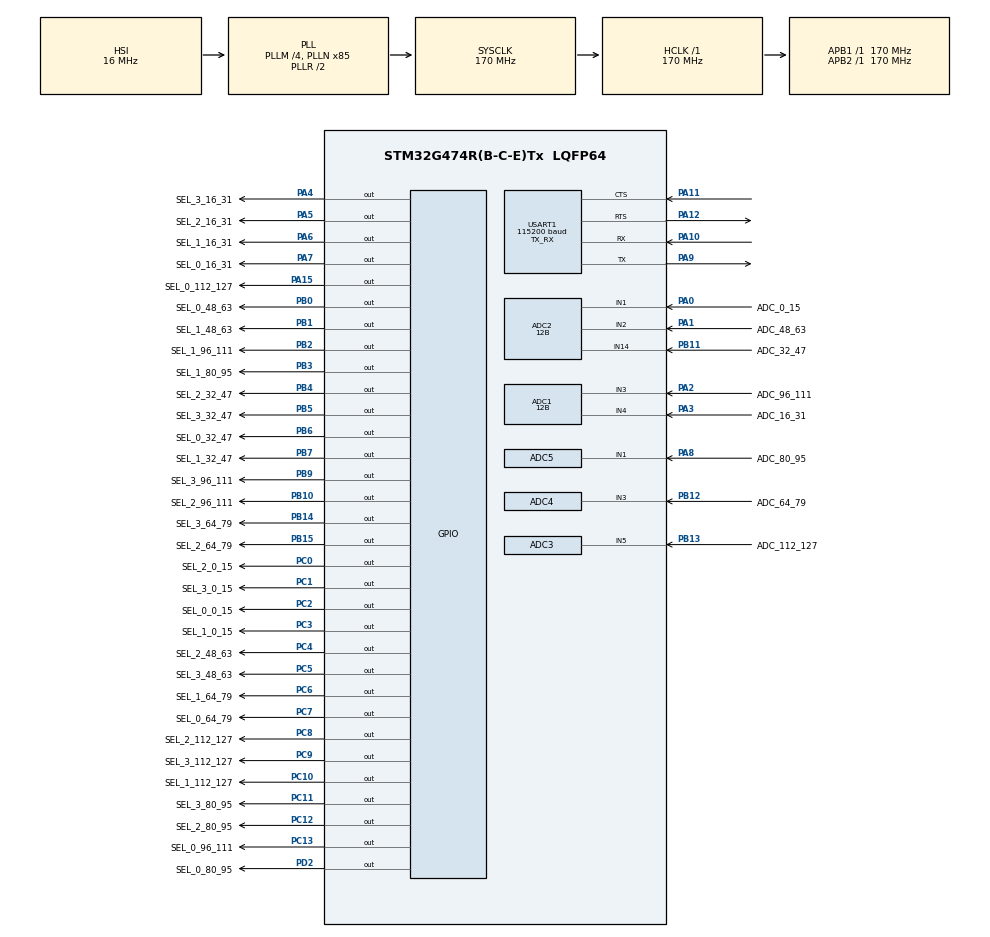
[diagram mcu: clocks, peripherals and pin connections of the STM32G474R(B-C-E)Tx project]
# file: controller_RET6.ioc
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ADC1.Channel-1\#ChannelRegularConversion=ADC_CHANNEL_3
ADC1.Channel-2\#ChannelRegularConversion=ADC_CHANNEL_4
ADC1.Channel-IN3=ADC_CHANNEL_3
ADC1.Channel-IN4=ADC_CHANNEL_4
ADC1.ClockPrescaler=ADC_CLOCK_SYNC_PCLK_DIV4
ADC1.ContinuousConvMode=DISABLE
ADC1.DMAContinuousRequests=ENABLE
ADC1.DataAlign=ADC_DATAALIGN_RIGHT
ADC1.DiscontinuousConvMode=DISABLE
ADC1.EOCSelection=ADC_EOC_SINGLE_CONV
ADC1.EnableAnalogWatchDog1=false
ADC1.EnableAnalogWatchDog2=false
ADC1.EnableAnalogWatchDog3=false
ADC1.EnableInjectedConversion=DISABLE
ADC1.EnableRegularConversion=ENABLE
ADC1.ExternalTrigConv=ADC_SOFTWARE_START
ADC1.ExternalTrigConvEdge=ADC_EXTERNALTRIGCONVEDGE_NONE
ADC1.GainCompensation=0
ADC1.LowPowerAutoWait=DISABLE
ADC1.Mode=ADC_MODE_INDEPENDENT
ADC1.NbrOfConversion=2
ADC1.OffsetNumber-1\#ChannelRegularConversion=ADC_OFFSET_NONE
ADC1.OffsetNumber-2\#ChannelRegularConversion=ADC_OFFSET_NONE
ADC1.Overrun=ADC_OVR_DATA_PRESERVED
ADC1.OversamplingMode=DISABLE
ADC1.Rank-1\#ChannelRegularConversion=1
ADC1.Rank-2\#ChannelRegularConversion=2
ADC1.Resolution=ADC_RESOLUTION_12B
ADC1.SamplingTime-1\#ChannelRegularConversion=ADC_SAMPLETIME_2CYCLES_5
ADC1.SamplingTime-2\#ChannelRegularConversion=ADC_SAMPLETIME_2CYCLES_5
ADC1.ScanConvMode=ADC_SCAN_ENABLE
ADC1.master=1
ADC2.Channel-1\#ChannelRegularConversion=ADC_CHANNEL_1
ADC2.Channel-2\#ChannelRegularConversion=ADC_CHANNEL_2
ADC2.Channel-3\#ChannelRegularConversion=ADC_CHANNEL_14
ADC2.Channel-IN1=ADC_CHANNEL_1
ADC2.Channel-IN14=ADC_CHANNEL_14
ADC2.Channel-IN2=ADC_CHANNEL_2
ADC2.ClockPrescaler=ADC_CLOCK_SYNC_PCLK_DIV4
ADC2.ContinuousConvMode=DISABLE
ADC2.DMAContinuousRequests=ENABLE
ADC2.DataAlign=ADC_DATAALIGN_RIGHT
ADC2.DiscontinuousConvMode=DISABLE
ADC2.EOCSelection=ADC_EOC_SINGLE_CONV
ADC2.EnableAnalogWatchDog1=false
ADC2.EnableAnalogWatchDog2=false
ADC2.EnableAnalogWatchDog3=false
ADC2.EnableInjectedConversion=DISABLE
ADC2.EnableRegularConversion=ENABLE
ADC2.ExternalTrigConv=ADC_SOFTWARE_START
ADC2.ExternalTrigConvEdge=ADC_EXTERNALTRIGCONVEDGE_NONE
ADC2.GainCompensation=0
ADC2.LowPowerAutoWait=DISABLE
ADC2.Mode=ADC_MODE_INDEPENDENT
ADC2.NbrOfConversion=3
ADC2.OffsetNumber-1\#ChannelRegularConversion=ADC_OFFSET_NONE
ADC2.OffsetNumber-2\#ChannelRegularConversion=ADC_OFFSET_NONE
ADC2.OffsetNumber-3\#ChannelRegularConversion=ADC_OFFSET_NONE
ADC2.Overrun=ADC_OVR_DATA_PRESERVED
ADC2.OversamplingMode=DISABLE
ADC2.Rank-1\#ChannelRegularConversion=1
ADC2.Rank-2\#ChannelRegularConversion=2
ADC2.Rank-3\#ChannelRegularConversion=3
ADC2.Resolution=ADC_RESOLUTION_12B
ADC2.SamplingTime-1\#ChannelRegularConversion=ADC_SAMPLETIME_2CYCLES_5
ADC2.SamplingTime-2\#ChannelRegularConversion=ADC_SAMPLETIME_2CYCLES_5
ADC2.SamplingTime-3\#ChannelRegularConversion=ADC_SAMPLETIME_2CYCLES_5
ADC2.ScanConvMode=ADC_SCAN_ENABLE
ADC3.Channel-0\#ChannelRegularConversion=ADC_CHANNEL_5
ADC3.Channel-IN5=ADC_CHANNEL_5
ADC3.ClockPrescaler=ADC_CLOCK_SYNC_PCLK_DIV4
ADC3.ContinuousConvMode=DISABLE
ADC3.DMAContinuousRequests=ENABLE
ADC3.DataAlign=ADC_DATAALIGN_RIGHT
ADC3.DiscontinuousConvMode=DISABLE
ADC3.EOCSelection=ADC_EOC_SINGLE_CONV
ADC3.EnableAnalogWatchDog1=false
ADC3.EnableAnalogWatchDog2=false
ADC3.EnableAnalogWatchDog3=false
ADC3.EnableInjectedConversion=DISABLE
ADC3.EnableRegularConversion=ENABLE
ADC3.ExternalTrigConv=ADC_SOFTWARE_START
ADC3.ExternalTrigConvEdge=ADC_EXTERNALTRIGCONVEDGE_NONE
ADC3.GainCompensation=0
ADC3.LowPowerAutoWait=DISABLE
ADC3.Mode=ADC_MODE_INDEPENDENT
ADC3.NbrOfConversion=1
ADC3.OffsetNumber-0\#ChannelRegularConversion=ADC_OFFSET_NONE
ADC3.Overrun=ADC_OVR_DATA_PRESERVED
ADC3.OversamplingMode=DISABLE
ADC3.Rank-0\#ChannelRegularConversion=1
ADC3.Resolution=ADC_RESOLUTION_12B
ADC3.SamplingTime-0\#ChannelRegularConversion=ADC_SAMPLETIME_2CYCLES_5
ADC3.ScanConvMode=ADC_SCAN_DISABLE
ADC3.master=1
ADC4.Channel-0\#ChannelRegularConversion=ADC_CHANNEL_3
ADC4.Channel-IN3=ADC_CHANNEL_3
ADC4.ClockPrescaler=ADC_CLOCK_SYNC_PCLK_DIV4
ADC4.ContinuousConvMode=DISABLE
ADC4.DMAContinuousRequests=ENABLE
ADC4.DataAlign=ADC_DATAALIGN_RIGHT
ADC4.DiscontinuousConvMode=DISABLE
ADC4.EOCSelection=ADC_EOC_SINGLE_CONV
ADC4.EnableAnalogWatchDog1=false
ADC4.EnableAnalogWatchDog2=false
ADC4.EnableAnalogWatchDog3=false
ADC4.EnableInjectedConversion=DISABLE
ADC4.EnableRegularConversion=ENABLE
ADC4.ExternalTrigConv=ADC_SOFTWARE_START
ADC4.ExternalTrigConvEdge=ADC_EXTERNALTRIGCONVEDGE_NONE
ADC4.GainCompensation=0
ADC4.LowPowerAutoWait=DISABLE
ADC4.Mode=ADC_MODE_INDEPENDENT
ADC4.NbrOfConversion=1
ADC4.OffsetNumber-0\#ChannelRegularConversion=ADC_OFFSET_NONE
ADC4.Overrun=ADC_OVR_DATA_PRESERVED
ADC4.OversamplingMode=DISABLE
ADC4.Rank-0\#ChannelRegularConversion=1
ADC4.Resolution=ADC_RESOLUTION_12B
ADC4.SamplingTime-0\#ChannelRegularConversion=ADC_SAMPLETIME_2CYCLES_5
ADC4.ScanConvMode=ADC_SCAN_DISABLE
ADC5.Channel-0\#ChannelRegularConversion=ADC_CHANNEL_1
ADC5.Channel-IN1=ADC_CHANNEL_1
ADC5.ClockPrescaler=ADC_CLOCK_SYNC_PCLK_DIV4
ADC5.ContinuousConvMode=DISABLE
ADC5.DMAContinuousRequests=ENABLE
ADC5.DataAlign=ADC_DATAALIGN_RIGHT
ADC5.DiscontinuousConvMode=DISABLE
ADC5.EOCSelection=ADC_EOC_SINGLE_CONV
ADC5.EnableAnalogWatchDog1=false
ADC5.EnableAnalogWatchDog2=false
ADC5.EnableAnalogWatchDog3=false
ADC5.EnableInjectedConversion=DISABLE
ADC5.EnableRegularConversion=ENABLE
ADC5.ExternalTrigConv=ADC_SOFTWARE_START
ADC5.ExternalTrigConvEdge=ADC_EXTERNALTRIGCONVEDGE_NONE
ADC5.GainCompensation=0
ADC5.LowPowerAutoWait=DISABLE
ADC5.NbrOfConversion=1
ADC5.OffsetNumber-0\#ChannelRegularConversion=ADC_OFFSET_NONE
ADC5.Overrun=ADC_OVR_DATA_PRESERVED
ADC5.OversamplingMode=DISABLE
ADC5.Rank-0\#ChannelRegularConversion=1
ADC5.Resolution=ADC_RESOLUTION_12B
ADC5.SamplingTime-0\#ChannelRegularConversion=ADC_SAMPLETIME_2CYCLES_5
ADC5.ScanConvMode=ADC_SCAN_DISABLE
CRC.DefaultInitValueUse=DEFAULT_INIT_VALUE_ENABLE
CRC.DefaultPolynomialUse=DEFAULT_POLYNOMIAL_ENABLE
CRC.InputDataFormat=CRC_INPUTDATA_FORMAT_BYTES
CRC.InputDataInversionMode=CRC_INPUTDATA_INVERSION_NONE
CRC.OutputDataInversionMode=CRC_OUTPUTDATA_INVERSION_DISABLE
Dma.ADC1.3.Direction=DMA_PERIPH_TO_MEMORY
Dma.ADC1.3.EventEnable=DISABLE
Dma.ADC1.3.Instance=DMA1_Channel2
Dma.ADC1.3.MemDataAlignment=DMA_MDATAALIGN_HALFWORD
Dma.ADC1.3.MemInc=DMA_MINC_ENABLE
Dma.ADC1.3.Mode=DMA_CIRCULAR
Dma.ADC1.3.PeriphDataAlignment=DMA_PDATAALIGN_HALFWORD
Dma.ADC1.3.PeriphInc=DMA_PINC_DISABLE
Dma.ADC1.3.Polarity=HAL_DMAMUX_REQ_GEN_RISING
Dma.ADC1.3.Priority=DMA_PRIORITY_VERY_HIGH
Dma.ADC1.3.RequestNumber=1
Dma.ADC1.3.SignalID=NONE
Dma.ADC1.3.SyncEnable=DISABLE
Dma.ADC1.3.SyncPolarity=HAL_DMAMUX_SYNC_NO_EVENT
Dma.ADC1.3.SyncRequestNumber=1
Dma.ADC1.3.SyncSignalID=NONE
Dma.ADC2.1.Direction=DMA_PERIPH_TO_MEMORY
Dma.ADC2.1.EventEnable=DISABLE
Dma.ADC2.1.Instance=DMA1_Channel3
Dma.ADC2.1.MemDataAlignment=DMA_MDATAALIGN_HALFWORD
Dma.ADC2.1.MemInc=DMA_MINC_ENABLE
Dma.ADC2.1.Mode=DMA_CIRCULAR
Dma.ADC2.1.PeriphDataAlignment=DMA_PDATAALIGN_HALFWORD
Dma.ADC2.1.PeriphInc=DMA_PINC_DISABLE
Dma.ADC2.1.Polarity=HAL_DMAMUX_REQ_GEN_RISING
Dma.ADC2.1.Priority=DMA_PRIORITY_VERY_HIGH
Dma.ADC2.1.RequestNumber=1
Dma.ADC2.1.SignalID=NONE
Dma.ADC2.1.SyncEnable=DISABLE
Dma.ADC2.1.SyncPolarity=HAL_DMAMUX_SYNC_NO_EVENT
Dma.ADC2.1.SyncRequestNumber=1
Dma.ADC2.1.SyncSignalID=NONE
Dma.ADC3.5.Direction=DMA_PERIPH_TO_MEMORY
Dma.ADC3.5.EventEnable=DISABLE
Dma.ADC3.5.Instance=DMA1_Channel4
Dma.ADC3.5.MemDataAlignment=DMA_MDATAALIGN_HALFWORD
Dma.ADC3.5.MemInc=DMA_MINC_ENABLE
Dma.ADC3.5.Mode=DMA_CIRCULAR
Dma.ADC3.5.PeriphDataAlignment=DMA_PDATAALIGN_HALFWORD
Dma.ADC3.5.PeriphInc=DMA_PINC_DISABLE
Dma.ADC3.5.Polarity=HAL_DMAMUX_REQ_GEN_RISING
Dma.ADC3.5.Priority=DMA_PRIORITY_VERY_HIGH
Dma.ADC3.5.RequestNumber=1
Dma.ADC3.5.SignalID=NONE
Dma.ADC3.5.SyncEnable=DISABLE
Dma.ADC3.5.SyncPolarity=HAL_DMAMUX_SYNC_NO_EVENT
Dma.ADC3.5.SyncRequestNumber=1
Dma.ADC3.5.SyncSignalID=NONE
Dma.ADC4.0.Direction=DMA_PERIPH_TO_MEMORY
Dma.ADC4.0.EventEnable=DISABLE
Dma.ADC4.0.Instance=DMA1_Channel5
Dma.ADC4.0.MemDataAlignment=DMA_MDATAALIGN_HALFWORD
Dma.ADC4.0.MemInc=DMA_MINC_ENABLE
Dma.ADC4.0.Mode=DMA_CIRCULAR
Dma.ADC4.0.PeriphDataAlignment=DMA_PDATAALIGN_HALFWORD
Dma.ADC4.0.PeriphInc=DMA_PINC_DISABLE
Dma.ADC4.0.Polarity=HAL_DMAMUX_REQ_GEN_RISING
Dma.ADC4.0.Priority=DMA_PRIORITY_VERY_HIGH
Dma.ADC4.0.RequestNumber=1
Dma.ADC4.0.SignalID=NONE
Dma.ADC4.0.SyncEnable=DISABLE
Dma.ADC4.0.SyncPolarity=HAL_DMAMUX_SYNC_NO_EVENT
Dma.ADC4.0.SyncRequestNumber=1
Dma.ADC4.0.SyncSignalID=NONE
Dma.ADC5.4.Direction=DMA_PERIPH_TO_MEMORY
Dma.ADC5.4.EventEnable=DISABLE
Dma.ADC5.4.Instance=DMA1_Channel6
Dma.ADC5.4.MemDataAlignment=DMA_MDATAALIGN_HALFWORD
Dma.ADC5.4.MemInc=DMA_MINC_ENABLE
Dma.ADC5.4.Mode=DMA_CIRCULAR
Dma.ADC5.4.PeriphDataAlignment=DMA_PDATAALIGN_HALFWORD
Dma.ADC5.4.PeriphInc=DMA_PINC_DISABLE
Dma.ADC5.4.Polarity=HAL_DMAMUX_REQ_GEN_RISING
Dma.ADC5.4.Priority=DMA_PRIORITY_VERY_HIGH
Dma.ADC5.4.RequestNumber=1
Dma.ADC5.4.SignalID=NONE
Dma.ADC5.4.SyncEnable=DISABLE
Dma.ADC5.4.SyncPolarity=HAL_DMAMUX_SYNC_NO_EVENT
Dma.ADC5.4.SyncRequestNumber=1
Dma.ADC5.4.SyncSignalID=NONE
Dma.Request0=ADC4
Dma.Request1=ADC2
Dma.Request2=USART1_TX
Dma.Request3=ADC1
Dma.Request4=ADC5
Dma.Request5=ADC3
Dma.USART1_TX.2.Direction=DMA_MEMORY_TO_PERIPH
Dma.USART1_TX.2.EventEnable=DISABLE
Dma.USART1_TX.2.Instance=DMA1_Channel1
Dma.USART1_TX.2.MemDataAlignment=DMA_MDATAALIGN_BYTE
Dma.USART1_TX.2.MemInc=DMA_MINC_ENABLE
Dma.USART1_TX.2.Mode=DMA_CIRCULAR
Dma.USART1_TX.2.PeriphDataAlignment=DMA_PDATAALIGN_BYTE
Dma.USART1_TX.2.PeriphInc=DMA_PINC_DISABLE
Dma.USART1_TX.2.Polarity=HAL_DMAMUX_REQ_GEN_RISING
Dma.USART1_TX.2.Priority=DMA_PRIORITY_MEDIUM
Dma.USART1_TX.2.RequestNumber=1
Dma.USART1_TX.2.SignalID=NONE
Dma.USART1_TX.2.SyncEnable=DISABLE
Dma.USART1_TX.2.SyncPolarity=HAL_DMAMUX_SYNC_NO_EVENT
Dma.USART1_TX.2.SyncRequestNumber=1
Dma.USART1_TX.2.SyncSignalID=NONE
HRTIM1.ADCTrigger_Id1=__NULL
HRTIM1.ADCTrigger_Id10=__NULL
HRTIM1.ADCTrigger_Id2=__NULL
HRTIM1.ADCTrigger_Id3=__NULL
HRTIM1.ADCTrigger_Id4=__NULL
HRTIM1.ADCTrigger_Id5=__NULL
HRTIM1.ADCTrigger_Id6=__NULL
HRTIM1.ADCTrigger_Id7=__NULL
HRTIM1.ADCTrigger_Id8=__NULL
HRTIM1.ADCTrigger_Id9=__NULL
HRTIM1.BurstDMAconfig-MasterTimer=__NULL
HRTIM1.BurstDMAconfig-No_output_TA=__NULL
HRTIM1.BurstDMAconfig-No_output_TB=__NULL
HRTIM1.BurstDMAconfig-No_output_TC=__NULL
HRTIM1.BurstMode-MasterTimer=HRTIM_TIMERBURSTMODE_MAINTAINCLOCK
HRTIM1.BurstMode-No_output_TA=HRTIM_TIMERBURSTMODE_MAINTAINCLOCK
HRTIM1.BurstMode-No_output_TB=HRTIM_TIMERBURSTMODE_MAINTAINCLOCK
HRTIM1.BurstMode-No_output_TC=HRTIM_TIMERBURSTMODE_MAINTAINCLOCK
HRTIM1.CalibrationRate_nonIT=HRTIM_CALIBRATIONRATE_3
HRTIM1.CaptureUnit1-No_output_TA=__NULL
HRTIM1.CaptureUnit1-No_output_TB=__NULL
HRTIM1.CaptureUnit1-No_output_TC=__NULL
HRTIM1.CaptureUnit2-No_output_TA=__NULL
HRTIM1.CaptureUnit2-No_output_TB=__NULL
HRTIM1.CaptureUnit2-No_output_TC=__NULL
HRTIM1.CompareUnit1-MasterTimer=__NULL
HRTIM1.CompareUnit1-No_output_TA=__NULL
HRTIM1.CompareUnit1-No_output_TB=__NULL
HRTIM1.CompareUnit1-No_output_TC=__NULL
HRTIM1.CompareUnit2-MasterTimer=__NULL
HRTIM1.CompareUnit2-No_output_TA=__NULL
HRTIM1.CompareUnit2-No_output_TB=__NULL
HRTIM1.CompareUnit2-No_output_TC=__NULL
HRTIM1.CompareUnit3-MasterTimer=__NULL
HRTIM1.CompareUnit3-No_output_TA=__NULL
HRTIM1.CompareUnit3-No_output_TB=__NULL
HRTIM1.CompareUnit3-No_output_TC=__NULL
HRTIM1.CompareUnit4-MasterTimer=__NULL
HRTIM1.CompareUnit4-No_output_TA=__NULL
HRTIM1.CompareUnit4-No_output_TB=__NULL
HRTIM1.CompareUnit4-No_output_TC=__NULL
HRTIM1.Configuration_TA=Waveform
HRTIM1.Configuration_TB=Waveform
HRTIM1.Configuration_TC=Waveform
HRTIM1.DACSynchro-MasterTimer=HRTIM_DACSYNC_NONE
HRTIM1.DACSynchro-No_output_TA=HRTIM_DACSYNC_NONE
HRTIM1.DACSynchro-No_output_TB=HRTIM_DACSYNC_NONE
HRTIM1.DACSynchro-No_output_TC=HRTIM_DACSYNC_NONE
HRTIM1.DeadTimeInsertion-No_output_TA=HRTIM_TIMDEADTIMEINSERTION_DISABLED
HRTIM1.DeadTimeInsertion-No_output_TB=HRTIM_TIMDEADTIMEINSERTION_DISABLED
HRTIM1.DeadTimeInsertion-No_output_TC=HRTIM_TIMDEADTIMEINSERTION_DISABLED
HRTIM1.DelayedProtectionMode-No_output_TA=HRTIM_TIMER_A_B_C_DELAYEDPROTECTION_DISABLED
HRTIM1.DelayedProtectionMode-No_output_TB=HRTIM_TIMER_A_B_C_DELAYEDPROTECTION_DISABLED
HRTIM1.DelayedProtectionMode-No_output_TC=HRTIM_TIMER_A_B_C_DELAYEDPROTECTION_DISABLED
HRTIM1.DualChannelDacEnableFake_TA-No_output_TA=HRTIM_TIMER_DCDE_DISABLED
HRTIM1.DualChannelDacEnableFake_TB-No_output_TB=HRTIM_TIMER_DCDE_DISABLED
HRTIM1.DualChannelDacEnableFake_TC-No_output_TC=HRTIM_TIMER_DCDE_DISABLED
HRTIM1.Enable=HRTIM_BURSTMODECTL_DISABLED
HRTIM1.EnableCalibration=DLLSimpleCalibration
HRTIM1.Event1-No_output_TA=__NULL
HRTIM1.Event1-No_output_TB=__NULL
HRTIM1.Event1-No_output_TC=__NULL
HRTIM1.Event10-No_output_TA=__NULL
HRTIM1.Event10-No_output_TB=__NULL
HRTIM1.Event10-No_output_TC=__NULL
HRTIM1.Event2-No_output_TA=__NULL
HRTIM1.Event2-No_output_TB=__NULL
HRTIM1.Event2-No_output_TC=__NULL
HRTIM1.Event3-No_output_TA=__NULL
HRTIM1.Event3-No_output_TB=__NULL
HRTIM1.Event3-No_output_TC=__NULL
HRTIM1.Event4-No_output_TA=__NULL
HRTIM1.Event4-No_output_TB=__NULL
HRTIM1.Event4-No_output_TC=__NULL
HRTIM1.Event5-No_output_TA=__NULL
HRTIM1.Event5-No_output_TB=__NULL
HRTIM1.Event5-No_output_TC=__NULL
HRTIM1.Event6-No_output_TA=__NULL
HRTIM1.Event6-No_output_TB=__NULL
HRTIM1.Event6-No_output_TC=__NULL
HRTIM1.Event7-No_output_TA=__NULL
HRTIM1.Event7-No_output_TB=__NULL
HRTIM1.Event7-No_output_TC=__NULL
HRTIM1.Event8-No_output_TA=__NULL
HRTIM1.Event8-No_output_TB=__NULL
HRTIM1.Event8-No_output_TC=__NULL
HRTIM1.Event9-No_output_TA=__NULL
HRTIM1.Event9-No_output_TB=__NULL
HRTIM1.Event9-No_output_TC=__NULL
HRTIM1.EventEnableA-No_output_TA=__NULL
HRTIM1.EventEnableA-No_output_TB=__NULL
HRTIM1.EventEnableA-No_output_TC=__NULL
HRTIM1.Event_EEV1=__NULL
HRTIM1.Event_EEV10=__NULL
HRTIM1.Event_EEV2=__NULL
HRTIM1.Event_EEV3=__NULL
HRTIM1.Event_EEV4=__NULL
HRTIM1.Event_EEV5=__NULL
HRTIM1.Event_EEV6=__NULL
HRTIM1.Event_EEV7=__NULL
HRTIM1.Event_EEV8=__NULL
HRTIM1.Event_EEV9=__NULL
HRTIM1.FaultLock-No_output_TA=HRTIM_TIMFAULTLOCK_READWRITE
HRTIM1.FaultLock-No_output_TB=HRTIM_TIMFAULTLOCK_READWRITE
HRTIM1.FaultLock-No_output_TC=HRTIM_TIMFAULTLOCK_READWRITE
HRTIM1.Fault_Line1=__NULL
HRTIM1.Fault_Line2=__NULL
HRTIM1.Fault_Line3=__NULL
HRTIM1.Fault_Line4=__NULL
HRTIM1.Fault_Line5=__NULL
HRTIM1.Fault_Line6=__NULL
HRTIM1.HRTIMInterruptResquests1=HRTIM_IT_SYSFLT
HRTIM1.HRTIMInterruptResquests2=HRTIM_IT_SYSFLT
HRTIM1.HRTIMInterruptResquests3=HRTIM_IT_SYSFLT
HRTIM1.HRTIMInterruptResquests4=HRTIM_IT_SYSFLT
HRTIM1.HRTIMInterruptResquests5=HRTIM_IT_SYSFLT
HRTIM1.HRTIMInterruptResquests6=HRTIM_IT_SYSFLT
HRTIM1.HRTIMInterruptResquests7=HRTIM_IT_SYSFLT
HRTIM1.HRTIMInterruptResquests8=HRTIM_IT_SYSFLT
HRTIM1.HRTIMInterruptResquests9=HRTIM_IT_SYSFLT
HRTIM1.InterleavedMode-MasterTimer=HRTIM_INTERLEAVED_MODE_DISABLED
HRTIM1.InterleavedMode-No_output_TA=HRTIM_INTERLEAVED_MODE_DISABLED
HRTIM1.InterleavedMode-No_output_TB=HRTIM_INTERLEAVED_MODE_DISABLED
HRTIM1.InterleavedMode-No_output_TC=HRTIM_INTERLEAVED_MODE_DISABLED
HRTIM1.InterruptRequests1-No_output_TA=HRTIM_TIM_IT_REP
HRTIM1.InterruptRequests1-No_output_TB=HRTIM_TIM_IT_REP
HRTIM1.InterruptRequests1-No_output_TC=HRTIM_TIM_IT_REP
HRTIM1.ModeTimeBase-MasterTimer=HRTIM_MODE_CONTINUOUS
HRTIM1.ModeTimeBase-No_output_TA=HRTIM_MODE_CONTINUOUS
HRTIM1.ModeTimeBase-No_output_TB=HRTIM_MODE_CONTINUOUS
HRTIM1.ModeTimeBase-No_output_TC=HRTIM_MODE_CONTINUOUS
HRTIM1.NumberDMARequests_Master=0
HRTIM1.NumberDMARequests_TA=0
HRTIM1.NumberDMARequests_TB=0
HRTIM1.NumberDMARequests_TC=0
HRTIM1.NumberFaultEnable-No_output_TA=0
HRTIM1.NumberFaultEnable-No_output_TB=0
HRTIM1.NumberFaultEnable-No_output_TC=0
HRTIM1.NumberInterruptRequests-No_output_TA=1
HRTIM1.NumberInterruptRequests-No_output_TB=1
HRTIM1.NumberInterruptRequests-No_output_TC=1
HRTIM1.NumberInterruptRequests_Master-MasterTimer=0
HRTIM1.NumberResetTrigger-No_output_TA=0
HRTIM1.NumberResetTrigger-No_output_TB=0
HRTIM1.NumberResetTrigger-No_output_TC=0
HRTIM1.NumberUpdateTrigger-No_output_TA=0
HRTIM1.NumberUpdateTrigger-No_output_TB=0
HRTIM1.NumberUpdateTrigger-No_output_TC=0
HRTIM1.Periode_MASTER=96
HRTIM1.Periode_TA=0x7695
HRTIM1.Periode_TB=0xFFFD
HRTIM1.PreloadEnable-MasterTimer=HRTIM_PRELOAD_DISABLED
HRTIM1.PreloadEnable-No_output_TA=HRTIM_PRELOAD_ENABLED
HRTIM1.PreloadEnable-No_output_TB=HRTIM_PRELOAD_ENABLED
HRTIM1.PreloadEnable-No_output_TC=HRTIM_PRELOAD_ENABLED
HRTIM1.PrescalerRatio_MASTER=HRTIM_PRESCALERRATIO_MUL32
HRTIM1.PrescalerRatio_TA=HRTIM_PRESCALERRATIO_DIV4
HRTIM1.PrescalerRatio_TB=HRTIM_PRESCALERRATIO_DIV4
HRTIM1.PrescalerRatio_TC=HRTIM_PRESCALERRATIO_DIV4
HRTIM1.PushPull-No_output_TA=HRTIM_TIMPUSHPULLMODE_DISABLED
HRTIM1.PushPull-No_output_TB=HRTIM_TIMPUSHPULLMODE_DISABLED
HRTIM1.PushPull-No_output_TC=HRTIM_TIMPUSHPULLMODE_DISABLED
HRTIM1.ReSyncUpdate-No_output_TA=HRTIM_TIMERESYNC_UPDATE_UNCONDITIONAL
HRTIM1.ReSyncUpdate-No_output_TB=HRTIM_TIMERESYNC_UPDATE_UNCONDITIONAL
HRTIM1.ReSyncUpdate-No_output_TC=HRTIM_TIMERESYNC_UPDATE_UNCONDITIONAL
HRTIM1.RepetitionUpdate-MasterTimer=HRTIM_UPDATEONREPETITION_DISABLED
HRTIM1.RepetitionUpdate-No_output_TA=HRTIM_UPDATEONREPETITION_ENABLED
HRTIM1.RepetitionUpdate-No_output_TB=HRTIM_UPDATEONREPETITION_ENABLED
HRTIM1.RepetitionUpdate-No_output_TC=HRTIM_UPDATEONREPETITION_ENABLED
HRTIM1.ResetOnSync-MasterTimer=HRTIM_SYNCRESET_DISABLED
HRTIM1.ResetOnSync-No_output_TA=HRTIM_SYNCRESET_DISABLED
HRTIM1.ResetOnSync-No_output_TB=HRTIM_SYNCRESET_DISABLED
HRTIM1.ResetOnSync-No_output_TC=HRTIM_SYNCRESET_DISABLED
HRTIM1.ResetUpdate-No_output_TA=HRTIM_TIMUPDATEONRESET_DISABLED
HRTIM1.ResetUpdate-No_output_TB=HRTIM_TIMUPDATEONRESET_DISABLED
HRTIM1.ResetUpdate-No_output_TC=HRTIM_TIMUPDATEONRESET_DISABLED
HRTIM1.StartOnSync-MasterTimer=HRTIM_SYNCSTART_DISABLED
HRTIM1.StartOnSync-No_output_TA=HRTIM_SYNCSTART_DISABLED
HRTIM1.StartOnSync-No_output_TB=HRTIM_SYNCSTART_DISABLED
HRTIM1.StartOnSync-No_output_TC=HRTIM_SYNCSTART_DISABLED
HRTIM1.SyncOptions=HRTIM_SYNCOPTION_NONE
HRTIM1.Timeout=10
HRTIM1.TimerIdx-MasterTimer=HRTIM_TIMERINDEX_MASTER
HRTIM1.TimerIdx-No_output_TA=HRTIM_TIMERINDEX_TIMER_A
HRTIM1.TimerIdx-No_output_TB=HRTIM_TIMERINDEX_TIMER_B
HRTIM1.TimerIdx-No_output_TC=HRTIM_TIMERINDEX_TIMER_C
HRTIM1.UpDownMode-No_output_TA=HRTIM_TIMERUPDOWNMODE_UP
HRTIM1.UpDownMode-No_output_TB=HRTIM_TIMERUPDOWNMODE_UP
HRTIM1.UpDownMode-No_output_TC=HRTIM_TIMERUPDOWNMODE_UP
HRTIM1.UpdateGating-MasterTimer=HRTIM_UPDATEGATING_INDEPENDENT
HRTIM1.UpdateGating-No_output_TA=HRTIM_UPDATEGATING_INDEPENDENT
HRTIM1.UpdateGating-No_output_TB=HRTIM_UPDATEGATING_INDEPENDENT
HRTIM1.UpdateGating-No_output_TC=HRTIM_UPDATEGATING_INDEPENDENT
Mcu.Family=STM32G4
Mcu.Name=STM32G474R(B-C-E)Tx
Mcu.Package=LQFP64
NVIC.DMA1_Channel1_IRQn=true\:0\:0\:false\:false\:true\:false\:true\:true
NVIC.DMA1_Channel2_IRQn=true\:0\:0\:false\:false\:true\:false\:true\:true
NVIC.DMA1_Channel3_IRQn=true\:0\:0\:false\:false\:true\:false\:true\:true
NVIC.DMA1_Channel4_IRQn=true\:0\:0\:false\:false\:true\:false\:true\:true
NVIC.DMA1_Channel5_IRQn=true\:0\:0\:false\:false\:true\:false\:true\:true
NVIC.DMA1_Channel6_IRQn=true\:0\:0\:false\:false\:true\:false\:true\:true
NVIC.HRTIM1_FLT_IRQn=true\:5\:0\:true\:false\:true\:true\:true\:true
NVIC.HRTIM1_Master_IRQn=true\:5\:0\:true\:false\:true\:true\:true\:true
NVIC.HRTIM1_TIMA_IRQn=true\:5\:0\:true\:false\:true\:true\:true\:true
NVIC.HRTIM1_TIMB_IRQn=true\:0\:0\:false\:false\:true\:true\:true\:true
NVIC.HRTIM1_TIMC_IRQn=true\:0\:0\:false\:false\:true\:true\:true\:true
NVIC.PriorityGroup=NVIC_PRIORITYGROUP_4
NVIC.TIM1_UP_TIM16_IRQn=true\:5\:0\:true\:false\:true\:true\:true\:true
NVIC.USART1_IRQn=true\:0\:0\:false\:false\:true\:true\:true\:true
PA0.GPIO_Label=ADC_0_15
PA0.Mode=IN1-Single-Ended
PA0.Signal=ADC2_IN1
PA1.GPIO_Label=ADC_48_63
PA1.Mode=IN2-Single-Ended
PA1.Signal=ADC2_IN2
PA10.Mode=Asynchronous
PA10.Signal=USART1_RX
PA11.Mode=CTS_RTS
PA11.Signal=USART1_CTS
PA12.Mode=CTS_RTS
PA12.Signal=USART1_RTS
PA13.Mode=Serial_Wire
PA13.Signal=SYS_JTMS-SWDIO
PA14.Mode=Serial_Wire
PA14.Signal=SYS_JTCK-SWCLK
PA15.GPIO_Label=SEL_0_112_127
PA15.GPIO_Speed=GPIO_SPEED_FREQ_VERY_HIGH
PA15.Signal=GPIO_Output
PA2.GPIO_Label=ADC_96_111
PA2.Mode=IN3-Single-Ended
PA2.Signal=ADC1_IN3
PA3.GPIO_Label=ADC_16_31
PA3.Mode=IN4-Single-Ended
PA3.Signal=ADC1_IN4
PA4.GPIO_Label=SEL_3_16_31
PA4.GPIO_Speed=GPIO_SPEED_FREQ_VERY_HIGH
PA4.Signal=GPIO_Output
PA5.GPIO_Label=SEL_2_16_31
PA5.GPIO_Speed=GPIO_SPEED_FREQ_VERY_HIGH
PA5.Signal=GPIO_Output
PA6.GPIO_Label=SEL_1_16_31
PA6.GPIO_Speed=GPIO_SPEED_FREQ_VERY_HIGH
PA6.Signal=GPIO_Output
PA7.GPIO_Label=SEL_0_16_31
PA7.GPIO_Speed=GPIO_SPEED_FREQ_VERY_HIGH
PA7.Signal=GPIO_Output
PA8.GPIO_Label=ADC_80_95
PA8.Mode=IN1-Single-Ended
PA8.Signal=ADC5_IN1
PA9.Mode=Asynchronous
PA9.Signal=USART1_TX
PB0.GPIO_Label=SEL_0_48_63
PB0.GPIO_Speed=GPIO_SPEED_FREQ_VERY_HIGH
PB0.Signal=GPIO_Output
PB1.GPIO_Label=SEL_1_48_63
PB1.GPIO_Speed=GPIO_SPEED_FREQ_VERY_HIGH
PB1.Signal=GPIO_Output
PB10.GPIO_Label=SEL_2_96_111
PB10.GPIO_Speed=GPIO_SPEED_FREQ_VERY_HIGH
PB10.Signal=GPIO_Output
PB11.GPIO_Label=ADC_32_47
PB11.Mode=IN14-Single-Ended
PB11.Signal=ADC2_IN14
PB12.GPIO_Label=ADC_64_79
PB12.Mode=IN3-Single-Ended
PB12.Signal=ADC4_IN3
PB13.GPIO_Label=ADC_112_127
PB13.Mode=IN5-Single-Ended
PB13.Signal=ADC3_IN5
PB14.GPIO_Label=SEL_3_64_79
PB14.GPIO_Speed=GPIO_SPEED_FREQ_VERY_HIGH
PB14.Signal=GPIO_Output
PB15.GPIO_Label=SEL_2_64_79
PB15.GPIO_Speed=GPIO_SPEED_FREQ_VERY_HIGH
PB15.Signal=GPIO_Output
PB2.GPIO_Label=SEL_1_96_111
PB2.GPIO_Speed=GPIO_SPEED_FREQ_VERY_HIGH
PB2.Signal=GPIO_Output
PB3.GPIO_Label=SEL_1_80_95
PB3.GPIO_Speed=GPIO_SPEED_FREQ_VERY_HIGH
PB3.Signal=GPIO_Output
PB4.GPIO_Label=SEL_2_32_47
PB4.GPIO_Speed=GPIO_SPEED_FREQ_VERY_HIGH
PB4.Signal=GPIO_Output
PB5.GPIO_Label=SEL_3_32_47
PB5.GPIO_Speed=GPIO_SPEED_FREQ_VERY_HIGH
PB5.Signal=GPIO_Output
PB6.GPIO_FM6=SYSCFG_FASTMODEPLUS_PB6
PB6.GPIO_Label=SEL_0_32_47
PB6.GPIO_Speed=GPIO_SPEED_FREQ_VERY_HIGH
PB6.Signal=GPIO_Output
PB7.GPIO_FM7=SYSCFG_FASTMODEPLUS_PB7
PB7.GPIO_Label=SEL_1_32_47
PB7.GPIO_Speed=GPIO_SPEED_FREQ_VERY_HIGH
PB7.Signal=GPIO_Output
PB9.GPIO_FM9=SYSCFG_FASTMODEPLUS_PB9
PB9.GPIO_Label=SEL_3_96_111
PB9.GPIO_Speed=GPIO_SPEED_FREQ_VERY_HIGH
PB9.Signal=GPIO_Output
PC0.GPIO_Label=SEL_2_0_15
PC0.GPIO_Speed=GPIO_SPEED_FREQ_VERY_HIGH
PC0.Signal=GPIO_Output
PC1.GPIO_Label=SEL_3_0_15
PC1.GPIO_Speed=GPIO_SPEED_FREQ_VERY_HIGH
PC1.Signal=GPIO_Output
PC10.GPIO_Label=SEL_1_112_127
PC10.GPIO_Speed=GPIO_SPEED_FREQ_VERY_HIGH
PC10.Signal=GPIO_Output
PC11.GPIO_Label=SEL_3_80_95
PC11.GPIO_Speed=GPIO_SPEED_FREQ_VERY_HIGH
PC11.Signal=GPIO_Output
PC12.GPIO_Label=SEL_2_80_95
PC12.GPIO_Speed=GPIO_SPEED_FREQ_VERY_HIGH
PC12.Signal=GPIO_Output
PC13.GPIO_Label=SEL_0_96_111
PC13.GPIO_Speed=GPIO_SPEED_FREQ_LOW
PC13.Signal=GPIO_Output
PC14-OSC32_IN.Mode=LSE-External-Oscillator
PC14-OSC32_IN.Signal=RCC_OSC32_IN
PC15-OSC32_OUT.Mode=LSE-External-Oscillator
PC15-OSC32_OUT.Signal=RCC_OSC32_OUT
PC2.GPIO_Label=SEL_0_0_15
PC2.GPIO_Speed=GPIO_SPEED_FREQ_VERY_HIGH
PC2.Signal=GPIO_Output
PC3.GPIO_Label=SEL_1_0_15
PC3.GPIO_Speed=GPIO_SPEED_FREQ_VERY_HIGH
PC3.Signal=GPIO_Output
PC4.GPIO_Label=SEL_2_48_63
PC4.GPIO_Speed=GPIO_SPEED_FREQ_VERY_HIGH
PC4.Signal=GPIO_Output
PC5.GPIO_Label=SEL_3_48_63
PC5.GPIO_Speed=GPIO_SPEED_FREQ_VERY_HIGH
PC5.Signal=GPIO_Output
PC6.GPIO_Label=SEL_1_64_79
PC6.GPIO_Speed=GPIO_SPEED_FREQ_VERY_HIGH
PC6.Signal=GPIO_Output
PC7.GPIO_Label=SEL_0_64_79
PC7.GPIO_Speed=GPIO_SPEED_FREQ_VERY_HIGH
PC7.Signal=GPIO_Output
PC8.GPIO_Label=SEL_2_112_127
PC8.GPIO_Speed=GPIO_SPEED_FREQ_VERY_HIGH
PC8.Signal=GPIO_Output
PC9.GPIO_Label=SEL_3_112_127
PC9.GPIO_Speed=GPIO_SPEED_FREQ_VERY_HIGH
PC9.Signal=GPIO_Output
PD2.GPIO_Label=SEL_0_80_95
PD2.GPIO_Speed=GPIO_SPEED_FREQ_VERY_HIGH
PD2.Signal=GPIO_Output
PF0-OSC_IN.Mode=HSE-External-Oscillator
PF0-OSC_IN.Signal=RCC_OSC_IN
PF1-OSC_OUT.Mode=HSE-External-Oscillator
PF1-OSC_OUT.Signal=RCC_OSC_OUT
ProjectManager.HeapSize=0x200
ProjectManager.StackSize=0x400
ProjectManager.TargetToolchain=MDK-ARM V5
RCC.ADC12Freq_Value=170000000
RCC.ADC345Freq_Value=170000000
RCC.AHBFreq_Value=170000000
RCC.APB1Freq_Value=170000000
RCC.APB1TimFreq_Value=170000000
RCC.APB2Freq_Value=170000000
RCC.APB2TimFreq_Value=170000000
RCC.CortexFreq_Value=170000000
RCC.EXTERNAL_CLOCK_VALUE=12288000
RCC.FLatency=FLASH_LATENCY_4
RCC.HCLKFreq_Value=170000000
RCC.HSE_VALUE=8000000
RCC.HSI48_VALUE=48000000
RCC.HSI_VALUE=16000000
RCC.PLLM=RCC_PLLM_DIV4
RCC.PLLN=85
RCC.PWR_Regulator_Voltage_Scale=PWR_REGULATOR_VOLTAGE_SCALE1_BOOST
RCC.SYSCLKFreq_VALUE=170000000
RCC.SYSCLKSource=RCC_SYSCLKSOURCE_PLLCLK
RCC.USBFreq_Value=170000000
RCC.VCOOutputFreq_Value=340000000
RTC.AsynchPrediv=127
RTC.Date=26
RTC.DayLightSaving=RTC_DAYLIGHTSAVING_NONE
RTC.Format=RTC_FORMAT_BCD
RTC.HourFormat=RTC_HOURFORMAT_24
RTC.Hours=18
RTC.Minutes=56
RTC.Month=RTC_MONTH_FEBRUARY
RTC.Seconds=0
RTC.StoreOperation=RTC_STOREOPERATION_RESET
RTC.SynchPrediv=255
RTC.WeekDay=RTC_WEEKDAY_WEDNESDAY
RTC.Year=25
SYS.TrimmingMode=__NULL
SYS.VoltageScaling=SYSCFG_VREFBUF_VOLTAGE_SCALE0
TIM1.AutoReloadPreload=TIM_AUTORELOAD_PRELOAD_DISABLE
TIM1.ClockDivision=TIM_CLOCKDIVISION_DIV1
TIM1.CounterMode=TIM_COUNTERMODE_UP
TIM1.Dithering=Disable
TIM1.PeriodNoDither=0
TIM1.Prescaler=0
TIM1.RepetitionCounter=0
TIM1.TIM_MasterOutputTrigger=TIM_TRGO_RESET
TIM1.TIM_MasterOutputTrigger2=TIM_TRGO2_RESET
TIM1.TIM_MasterSlaveMode=TIM_MASTERSLAVEMODE_DISABLE
USART1.AutoBaudRateEnableParam=UART_ADVFEATURE_AUTOBAUDRATE_DISABLE
USART1.BaudRate=115200
USART1.ClockPrescaler=PRESCALER_DIV1
USART1.DMADisableonRxErrorParam=ADVFEATURE_DMA_ENABLEONRXERROR
USART1.DataInvertParam=ADVFEATURE_DATAINV_DISABLE
USART1.FIFOMode=FIFOMODE_DISABLE
USART1.MSBFirstParam=ADVFEATURE_MSBFIRST_DISABLE
USART1.Mode=MODE_TX_RX
USART1.OneBitSampling=UART_ONE_BIT_SAMPLE_DISABLE
USART1.OverSampling=UART_OVERSAMPLING_16
USART1.OverrunDisableParam=ADVFEATURE_OVERRUN_ENABLE
USART1.Parity=PARITY_NONE
USART1.RXFIFOThreshold=RXFIFO_THRESHOLD_1EIGHTHFULL
USART1.RxPinLevelInvertParam=ADVFEATURE_RXINV_DISABLE
USART1.StopBits=STOPBITS_1
USART1.SwapParam=ADVFEATURE_SWAP_DISABLE
USART1.TXFIFOThreshold=TXFIFO_THRESHOLD_1EIGHTHFULL
USART1.TxPinLevelInvertParam=ADVFEATURE_TXINV_DISABLE
USART1.VirtualMode-Asynchronous=VM_ASYNC
USART1.WordLength=WORDLENGTH_8B
VP_CRC_VS_CRC.Mode=CRC_Activate
VP_HRTIM1_VS_hrtimMasterTimerNoOutput.Mode=MasterTimer
VP_HRTIM1_VS_hrtimTimerANoOutput.Mode=No_output_TA
VP_HRTIM1_VS_hrtimTimerBNoOutput.Mode=No_output_TB
VP_HRTIM1_VS_hrtimTimerCNoOutput.Mode=No_output_TC
VP_HRTIM1_VirtualSync.Mode=SCOUT_SCINmodeVirtual
VP_RTC_VS_RTC_Activate.Mode=RTC_Enabled
VP_RTC_VS_RTC_Calendar.Mode=RTC_Calendar
VP_SYS_VS_DBSignals.Mode=DisableDeadBatterySignals
VP_TIM1_VS_ClockSourceINT.Mode=Internal
VREF+.Mode=InternalMode
VREF+.Signal=VREFBUF_OUT
board=custom

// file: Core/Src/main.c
/* USER CODE BEGIN Header */
/**
  ******************************************************************************
  * @file           : main.c
  * @brief          : Main program body
  ******************************************************************************
  * @attention
  *
  * Copyright (c) 2025 STMicroelectronics.
  * All rights reserved.
  *
  * This software is licensed under terms that can be found in the LICENSE file
  * in the root directory of this software component.
  * If no LICENSE file comes with this software, it is provided AS-IS.
  *
  ******************************************************************************
  */
/* USER CODE END Header */
#include "main.h"

/* USER CODE BEGIN Includes */
#include "switch.h"
#include <string.h>
#include "adc_task.h"
#include "dsp_task.h"
/* USER CODE END Includes */

ADC_HandleTypeDef hadc1;
ADC_HandleTypeDef hadc2;
ADC_HandleTypeDef hadc3;
ADC_HandleTypeDef hadc4;
ADC_HandleTypeDef hadc5;
DMA_HandleTypeDef hdma_adc1;
DMA_HandleTypeDef hdma_adc2;
DMA_HandleTypeDef hdma_adc3;
DMA_HandleTypeDef hdma_adc4;
DMA_HandleTypeDef hdma_adc5;

CRC_HandleTypeDef hcrc;

HRTIM_HandleTypeDef hhrtim1;

RTC_HandleTypeDef hrtc;

TIM_HandleTypeDef htim1;

UART_HandleTypeDef huart1;
DMA_HandleTypeDef hdma_usart1_tx;

/* USER CODE BEGIN PV */
VLP_packet_t VLP_packet;
/* USER CODE END PV */

void SystemClock_Config(void);
static void MX_GPIO_Init(void);
static void MX_DMA_Init(void);
static void MX_ADC1_Init(void);
static void MX_ADC2_Init(void);
static void MX_ADC3_Init(void);
static void MX_ADC4_Init(void);
static void MX_ADC5_Init(void);
static void MX_CRC_Init(void);
static void MX_USART1_UART_Init(void);
static void MX_HRTIM1_Init(void);
static void MX_TIM1_Init(void);
static void MX_RTC_Init(void);

int main(void)
{

  /* MCU Configuration--------------------------------------------------------*/

  /* Reset of all peripherals, Initializes the Flash interface and the Systick. */
  HAL_Init();

  /* USER CODE BEGIN Init */
  VLP_packet.header = 0xDD;
	VLP_packet.header2 = 0x99;
  DSP_init();
  vlc_init();
  /* USER CODE END Init */

  /* Configure the system clock */
  SystemClock_Config();

  /* Initialize all configured peripherals */
  MX_GPIO_Init();
  MX_DMA_Init();
  MX_ADC1_Init();
  MX_ADC2_Init();
  MX_ADC3_Init();
  MX_ADC4_Init();
  MX_ADC5_Init();
  MX_CRC_Init();
  MX_USART1_UART_Init();
  MX_HRTIM1_Init();
  MX_TIM1_Init();
  MX_RTC_Init();

  /* Infinite loop */
  /* USER CODE BEGIN WHILE */
  while (1)
  {
    // dsp_task_watchdog = 0;
    // DSP_task();
    /* USER CODE END WHILE */

  }
}

void SystemClock_Config(void)
{
  RCC_OscInitTypeDef RCC_OscInitStruct = {0};
  RCC_ClkInitTypeDef RCC_ClkInitStruct = {0};

  /** Configure the main internal regulator output voltage
  */
  HAL_PWREx_ControlVoltageScaling(PWR_REGULATOR_VOLTAGE_SCALE1_BOOST);

  /** Initializes the RCC Oscillators according to the specified parameters
  * in the RCC_OscInitTypeDef structure.
  */
  RCC_OscInitStruct.OscillatorType = RCC_OSCILLATORTYPE_HSI|RCC_OSCILLATORTYPE_LSI;
  RCC_OscInitStruct.HSIState = RCC_HSI_ON;
  RCC_OscInitStruct.HSICalibrationValue = RCC_HSICALIBRATION_DEFAULT;
  RCC_OscInitStruct.LSIState = RCC_LSI_ON;
  RCC_OscInitStruct.PLL.PLLState = RCC_PLL_ON;
  RCC_OscInitStruct.PLL.PLLSource = RCC_PLLSOURCE_HSI;
  RCC_OscInitStruct.PLL.PLLM = RCC_PLLM_DIV4;
  RCC_OscInitStruct.PLL.PLLN = 85;
  RCC_OscInitStruct.PLL.PLLP = RCC_PLLP_DIV2;
  RCC_OscInitStruct.PLL.PLLQ = RCC_PLLQ_DIV2;
  RCC_OscInitStruct.PLL.PLLR = RCC_PLLR_DIV2;
  if (HAL_RCC_OscConfig(&RCC_OscInitStruct) != HAL_OK)
  {
    Error_Handler();
  }

  /** Initializes the CPU, AHB and APB buses clocks
  */
  RCC_ClkInitStruct.ClockType = RCC_CLOCKTYPE_HCLK|RCC_CLOCKTYPE_SYSCLK
                              |RCC_CLOCKTYPE_PCLK1|RCC_CLOCKTYPE_PCLK2;
  RCC_ClkInitStruct.SYSCLKSource = RCC_SYSCLKSOURCE_PLLCLK;
  RCC_ClkInitStruct.AHBCLKDivider = RCC_SYSCLK_DIV1;
  RCC_ClkInitStruct.APB1CLKDivider = RCC_HCLK_DIV1;
  RCC_ClkInitStruct.APB2CLKDivider = RCC_HCLK_DIV1;

  if (HAL_RCC_ClockConfig(&RCC_ClkInitStruct, FLASH_LATENCY_4) != HAL_OK)
  {
    Error_Handler();
  }
}

static void MX_ADC1_Init(void)
{

  ADC_MultiModeTypeDef multimode = {0};
  ADC_ChannelConfTypeDef sConfig = {0};

  /** Common config
  */
  hadc1.Instance = ADC1;
  hadc1.Init.ClockPrescaler = ADC_CLOCK_SYNC_PCLK_DIV4;
  hadc1.Init.Resolution = ADC_RESOLUTION_12B;
  hadc1.Init.DataAlign = ADC_DATAALIGN_RIGHT;
  hadc1.Init.GainCompensation = 0;
  hadc1.Init.ScanConvMode = ADC_SCAN_ENABLE;
  hadc1.Init.EOCSelection = ADC_EOC_SINGLE_CONV;
  hadc1.Init.LowPowerAutoWait = DISABLE;
  hadc1.Init.ContinuousConvMode = DISABLE;
  hadc1.Init.NbrOfConversion = 2;
  hadc1.Init.DiscontinuousConvMode = DISABLE;
  hadc1.Init.ExternalTrigConv = ADC_SOFTWARE_START;
  hadc1.Init.ExternalTrigConvEdge = ADC_EXTERNALTRIGCONVEDGE_NONE;
  hadc1.Init.DMAContinuousRequests = ENABLE;
  hadc1.Init.Overrun = ADC_OVR_DATA_PRESERVED;
  hadc1.Init.OversamplingMode = DISABLE;
  if (HAL_ADC_Init(&hadc1) != HAL_OK)
  {
    Error_Handler();
  }

  /** Configure the ADC multi-mode
  */
  multimode.Mode = ADC_MODE_INDEPENDENT;
  if (HAL_ADCEx_MultiModeConfigChannel(&hadc1, &multimode) != HAL_OK)
  {
    Error_Handler();
  }

  /** Configure Regular Channel
  */
  sConfig.Channel = ADC_CHANNEL_3;
  sConfig.Rank = ADC_REGULAR_RANK_1;
  sConfig.SamplingTime = ADC_SAMPLETIME_2CYCLES_5;
  sConfig.SingleDiff = ADC_SINGLE_ENDED;
  sConfig.OffsetNumber = ADC_OFFSET_NONE;
  sConfig.Offset = 0;
  if (HAL_ADC_ConfigChannel(&hadc1, &sConfig) != HAL_OK)
  {
    Error_Handler();
  }

  /** Configure Regular Channel
  */
  sConfig.Channel = ADC_CHANNEL_4;
  sConfig.Rank = ADC_REGULAR_RANK_2;
  if (HAL_ADC_ConfigChannel(&hadc1, &sConfig) != HAL_OK)
  {
    Error_Handler();
  }

}

static void MX_ADC2_Init(void)
{

  ADC_ChannelConfTypeDef sConfig = {0};

  /** Common config
  */
  hadc2.Instance = ADC2;
  hadc2.Init.ClockPrescaler = ADC_CLOCK_SYNC_PCLK_DIV4;
  hadc2.Init.Resolution = ADC_RESOLUTION_12B;
  hadc2.Init.DataAlign = ADC_DATAALIGN_RIGHT;
  hadc2.Init.GainCompensation = 0;
  hadc2.Init.ScanConvMode = ADC_SCAN_ENABLE;
  hadc2.Init.EOCSelection = ADC_EOC_SINGLE_CONV;
  hadc2.Init.LowPowerAutoWait = DISABLE;
  hadc2.Init.ContinuousConvMode = DISABLE;
  hadc2.Init.NbrOfConversion = 3;
  hadc2.Init.DiscontinuousConvMode = DISABLE;
  hadc2.Init.ExternalTrigConv = ADC_SOFTWARE_START;
  hadc2.Init.ExternalTrigConvEdge = ADC_EXTERNALTRIGCONVEDGE_NONE;
  hadc2.Init.DMAContinuousRequests = ENABLE;
  hadc2.Init.Overrun = ADC_OVR_DATA_PRESERVED;
  hadc2.Init.OversamplingMode = DISABLE;
  if (HAL_ADC_Init(&hadc2) != HAL_OK)
  {
    Error_Handler();
  }

  /** Configure Regular Channel
  */
  sConfig.Channel = ADC_CHANNEL_1;
  sConfig.Rank = ADC_REGULAR_RANK_1;
  sConfig.SamplingTime = ADC_SAMPLETIME_2CYCLES_5;
  sConfig.SingleDiff = ADC_SINGLE_ENDED;
  sConfig.OffsetNumber = ADC_OFFSET_NONE;
  sConfig.Offset = 0;
  if (HAL_ADC_ConfigChannel(&hadc2, &sConfig) != HAL_OK)
  {
    Error_Handler();
  }

  /** Configure Regular Channel
  */
  sConfig.Channel = ADC_CHANNEL_2;
  sConfig.Rank = ADC_REGULAR_RANK_2;
  if (HAL_ADC_ConfigChannel(&hadc2, &sConfig) != HAL_OK)
  {
    Error_Handler();
  }

  /** Configure Regular Channel
  */
  sConfig.Channel = ADC_CHANNEL_14;
  sConfig.Rank = ADC_REGULAR_RANK_3;
  if (HAL_ADC_ConfigChannel(&hadc2, &sConfig) != HAL_OK)
  {
    Error_Handler();
  }

}

static void MX_ADC3_Init(void)
{

  ADC_MultiModeTypeDef multimode = {0};
  ADC_ChannelConfTypeDef sConfig = {0};

  /** Common config
  */
  hadc3.Instance = ADC3;
  hadc3.Init.ClockPrescaler = ADC_CLOCK_SYNC_PCLK_DIV4;
  hadc3.Init.Resolution = ADC_RESOLUTION_12B;
  hadc3.Init.DataAlign = ADC_DATAALIGN_RIGHT;
  hadc3.Init.GainCompensation = 0;
  hadc3.Init.ScanConvMode = ADC_SCAN_DISABLE;
  hadc3.Init.EOCSelection = ADC_EOC_SINGLE_CONV;
  hadc3.Init.LowPowerAutoWait = DISABLE;
  hadc3.Init.ContinuousConvMode = DISABLE;
  hadc3.Init.NbrOfConversion = 1;
  hadc3.Init.DiscontinuousConvMode = DISABLE;
  hadc3.Init.ExternalTrigConv = ADC_SOFTWARE_START;
  hadc3.Init.ExternalTrigConvEdge = ADC_EXTERNALTRIGCONVEDGE_NONE;
  hadc3.Init.DMAContinuousRequests = ENABLE;
  hadc3.Init.Overrun = ADC_OVR_DATA_PRESERVED;
  hadc3.Init.OversamplingMode = DISABLE;
  if (HAL_ADC_Init(&hadc3) != HAL_OK)
  {
    Error_Handler();
  }

  /** Configure the ADC multi-mode
  */
  multimode.Mode = ADC_MODE_INDEPENDENT;
  if (HAL_ADCEx_MultiModeConfigChannel(&hadc3, &multimode) != HAL_OK)
  {
    Error_Handler();
  }

  /** Configure Regular Channel
  */
  sConfig.Channel = ADC_CHANNEL_5;
  sConfig.Rank = ADC_REGULAR_RANK_1;
  sConfig.SamplingTime = ADC_SAMPLETIME_2CYCLES_5;
  sConfig.SingleDiff = ADC_SINGLE_ENDED;
  sConfig.OffsetNumber = ADC_OFFSET_NONE;
  sConfig.Offset = 0;
  if (HAL_ADC_ConfigChannel(&hadc3, &sConfig) != HAL_OK)
  {
    Error_Handler();
  }

}

static void MX_ADC4_Init(void)
{

  ADC_ChannelConfTypeDef sConfig = {0};

  /** Common config
  */
  hadc4.Instance = ADC4;
  hadc4.Init.ClockPrescaler = ADC_CLOCK_SYNC_PCLK_DIV4;
  hadc4.Init.Resolution = ADC_RESOLUTION_12B;
  hadc4.Init.DataAlign = ADC_DATAALIGN_RIGHT;
  hadc4.Init.GainCompensation = 0;
  hadc4.Init.ScanConvMode = ADC_SCAN_DISABLE;
  hadc4.Init.EOCSelection = ADC_EOC_SINGLE_CONV;
  hadc4.Init.LowPowerAutoWait = DISABLE;
  hadc4.Init.ContinuousConvMode = DISABLE;
  hadc4.Init.NbrOfConversion = 1;
  hadc4.Init.DiscontinuousConvMode = DISABLE;
  hadc4.Init.ExternalTrigConv = ADC_SOFTWARE_START;
  hadc4.Init.ExternalTrigConvEdge = ADC_EXTERNALTRIGCONVEDGE_NONE;
  hadc4.Init.DMAContinuousRequests = ENABLE;
  hadc4.Init.Overrun = ADC_OVR_DATA_PRESERVED;
  hadc4.Init.OversamplingMode = DISABLE;
  if (HAL_ADC_Init(&hadc4) != HAL_OK)
  {
    Error_Handler();
  }

  /** Configure Regular Channel
  */
  sConfig.Channel = ADC_CHANNEL_3;
  sConfig.Rank = ADC_REGULAR_RANK_1;
  sConfig.SamplingTime = ADC_SAMPLETIME_2CYCLES_5;
  sConfig.SingleDiff = ADC_SINGLE_ENDED;
  sConfig.OffsetNumber = ADC_OFFSET_NONE;
  sConfig.Offset = 0;
  if (HAL_ADC_ConfigChannel(&hadc4, &sConfig) != HAL_OK)
  {
    Error_Handler();
  }

}

static void MX_ADC5_Init(void)
{

  ADC_ChannelConfTypeDef sConfig = {0};

  /** Common config
  */
  hadc5.Instance = ADC5;
  hadc5.Init.ClockPrescaler = ADC_CLOCK_SYNC_PCLK_DIV4;
  hadc5.Init.Resolution = ADC_RESOLUTION_12B;
  hadc5.Init.DataAlign = ADC_DATAALIGN_RIGHT;
  hadc5.Init.GainCompensation = 0;
  hadc5.Init.ScanConvMode = ADC_SCAN_DISABLE;
  hadc5.Init.EOCSelection = ADC_EOC_SINGLE_CONV;
  hadc5.Init.LowPowerAutoWait = DISABLE;
  hadc5.Init.ContinuousConvMode = DISABLE;
  hadc5.Init.NbrOfConversion = 1;
  hadc5.Init.DiscontinuousConvMode = DISABLE;
  hadc5.Init.ExternalTrigConv = ADC_SOFTWARE_START;
  hadc5.Init.ExternalTrigConvEdge = ADC_EXTERNALTRIGCONVEDGE_NONE;
  hadc5.Init.DMAContinuousRequests = ENABLE;
  hadc5.Init.Overrun = ADC_OVR_DATA_PRESERVED;
  hadc5.Init.OversamplingMode = DISABLE;
  if (HAL_ADC_Init(&hadc5) != HAL_OK)
  {
    Error_Handler();
  }

  /** Configure Regular Channel
  */
  sConfig.Channel = ADC_CHANNEL_1;
  sConfig.Rank = ADC_REGULAR_RANK_1;
  sConfig.SamplingTime = ADC_SAMPLETIME_2CYCLES_5;
  sConfig.SingleDiff = ADC_SINGLE_ENDED;
  sConfig.OffsetNumber = ADC_OFFSET_NONE;
  sConfig.Offset = 0;
  if (HAL_ADC_ConfigChannel(&hadc5, &sConfig) != HAL_OK)
  {
    Error_Handler();
  }

}

static void MX_CRC_Init(void)
{

  hcrc.Instance = CRC;
  hcrc.Init.DefaultPolynomialUse = DEFAULT_POLYNOMIAL_ENABLE;
  hcrc.Init.DefaultInitValueUse = DEFAULT_INIT_VALUE_ENABLE;
  hcrc.Init.InputDataInversionMode = CRC_INPUTDATA_INVERSION_NONE;
  hcrc.Init.OutputDataInversionMode = CRC_OUTPUTDATA_INVERSION_DISABLE;
  hcrc.InputDataFormat = CRC_INPUTDATA_FORMAT_BYTES;
  if (HAL_CRC_Init(&hcrc) != HAL_OK)
  {
    Error_Handler();
  }

}

static void MX_HRTIM1_Init(void)
{

  HRTIM_TimeBaseCfgTypeDef pTimeBaseCfg = {0};
  HRTIM_TimerCfgTypeDef pTimerCfg = {0};
  HRTIM_TimerCtlTypeDef pTimerCtl = {0};

  hhrtim1.Instance = HRTIM1;
  hhrtim1.Init.HRTIMInterruptResquests = HRTIM_IT_SYSFLT|HRTIM_IT_SYSFLT
                              |HRTIM_IT_SYSFLT|HRTIM_IT_SYSFLT
                              |HRTIM_IT_SYSFLT|HRTIM_IT_SYSFLT
                              |HRTIM_IT_SYSFLT|HRTIM_IT_SYSFLT
                              |HRTIM_IT_SYSFLT;
  hhrtim1.Init.SyncOptions = HRTIM_SYNCOPTION_NONE;
  if (HAL_HRTIM_Init(&hhrtim1) != HAL_OK)
  {
    Error_Handler();
  }
  if (HAL_HRTIM_DLLCalibrationStart(&hhrtim1, HRTIM_CALIBRATIONRATE_3) != HAL_OK)
  {
    Error_Handler();
  }
  if (HAL_HRTIM_PollForDLLCalibration(&hhrtim1, 10) != HAL_OK)
  {
    Error_Handler();
  }
  pTimeBaseCfg.Period = 96;
  pTimeBaseCfg.RepetitionCounter = 0x00;
  pTimeBaseCfg.PrescalerRatio = HRTIM_PRESCALERRATIO_MUL32;
  pTimeBaseCfg.Mode = HRTIM_MODE_CONTINUOUS;
  if (HAL_HRTIM_TimeBaseConfig(&hhrtim1, HRTIM_TIMERINDEX_MASTER, &pTimeBaseCfg) != HAL_OK)
  {
    Error_Handler();
  }
  pTimerCfg.InterruptRequests = HRTIM_MASTER_IT_NONE;
  pTimerCfg.DMARequests = HRTIM_MASTER_DMA_NONE;
  pTimerCfg.DMASrcAddress = 0x0000;
  pTimerCfg.DMADstAddress = 0x0000;
  pTimerCfg.DMASize = 0x1;
  pTimerCfg.HalfModeEnable = HRTIM_HALFMODE_DISABLED;
  pTimerCfg.InterleavedMode = HRTIM_INTERLEAVED_MODE_DISABLED;
  pTimerCfg.StartOnSync = HRTIM_SYNCSTART_DISABLED;
  pTimerCfg.ResetOnSync = HRTIM_SYNCRESET_DISABLED;
  pTimerCfg.DACSynchro = HRTIM_DACSYNC_NONE;
  pTimerCfg.PreloadEnable = HRTIM_PRELOAD_DISABLED;
  pTimerCfg.UpdateGating = HRTIM_UPDATEGATING_INDEPENDENT;
  pTimerCfg.BurstMode = HRTIM_TIMERBURSTMODE_MAINTAINCLOCK;
  pTimerCfg.RepetitionUpdate = HRTIM_UPDATEONREPETITION_DISABLED;
  pTimerCfg.ReSyncUpdate = HRTIM_TIMERESYNC_UPDATE_UNCONDITIONAL;
  if (HAL_HRTIM_WaveformTimerConfig(&hhrtim1, HRTIM_TIMERINDEX_MASTER, &pTimerCfg) != HAL_OK)
  {
    Error_Handler();
  }
  pTimeBaseCfg.Period = 0x7695;
  pTimeBaseCfg.PrescalerRatio = HRTIM_PRESCALERRATIO_DIV4;
  if (HAL_HRTIM_TimeBaseConfig(&hhrtim1, HRTIM_TIMERINDEX_TIMER_A, &pTimeBaseCfg) != HAL_OK)
  {
    Error_Handler();
  }
  pTimerCtl.UpDownMode = HRTIM_TIMERUPDOWNMODE_UP;
  pTimerCtl.DualChannelDacEnable = HRTIM_TIMER_DCDE_DISABLED;
  if (HAL_HRTIM_WaveformTimerControl(&hhrtim1, HRTIM_TIMERINDEX_TIMER_A, &pTimerCtl) != HAL_OK)
  {
    Error_Handler();
  }
  pTimerCfg.InterruptRequests = HRTIM_TIM_IT_REP;
  pTimerCfg.DMARequests = HRTIM_TIM_DMA_NONE;
  pTimerCfg.PreloadEnable = HRTIM_PRELOAD_ENABLED;
  pTimerCfg.RepetitionUpdate = HRTIM_UPDATEONREPETITION_ENABLED;
  pTimerCfg.PushPull = HRTIM_TIMPUSHPULLMODE_DISABLED;
  pTimerCfg.FaultEnable = HRTIM_TIMFAULTENABLE_NONE;
  pTimerCfg.FaultLock = HRTIM_TIMFAULTLOCK_READWRITE;
  pTimerCfg.DeadTimeInsertion = HRTIM_TIMDEADTIMEINSERTION_DISABLED;
  pTimerCfg.DelayedProtectionMode = HRTIM_TIMER_A_B_C_DELAYEDPROTECTION_DISABLED;
  pTimerCfg.UpdateTrigger = HRTIM_TIMUPDATETRIGGER_NONE;
  pTimerCfg.ResetTrigger = HRTIM_TIMRESETTRIGGER_NONE;
  pTimerCfg.ResetUpdate = HRTIM_TIMUPDATEONRESET_DISABLED;
  if (HAL_HRTIM_WaveformTimerConfig(&hhrtim1, HRTIM_TIMERINDEX_TIMER_A, &pTimerCfg) != HAL_OK)
  {
    Error_Handler();
  }
  if (HAL_HRTIM_WaveformTimerConfig(&hhrtim1, HRTIM_TIMERINDEX_TIMER_B, &pTimerCfg) != HAL_OK)
  {
    Error_Handler();
  }
  if (HAL_HRTIM_WaveformTimerConfig(&hhrtim1, HRTIM_TIMERINDEX_TIMER_C, &pTimerCfg) != HAL_OK)
  {
    Error_Handler();
  }
  pTimeBaseCfg.Period = 0xFFFD;
  if (HAL_HRTIM_TimeBaseConfig(&hhrtim1, HRTIM_TIMERINDEX_TIMER_B, &pTimeBaseCfg) != HAL_OK)
  {
    Error_Handler();
  }
  if (HAL_HRTIM_WaveformTimerControl(&hhrtim1, HRTIM_TIMERINDEX_TIMER_B, &pTimerCtl) != HAL_OK)
  {
    Error_Handler();
  }
  if (HAL_HRTIM_TimeBaseConfig(&hhrtim1, HRTIM_TIMERINDEX_TIMER_C, &pTimeBaseCfg) != HAL_OK)
  {
    Error_Handler();
  }
  if (HAL_HRTIM_WaveformTimerControl(&hhrtim1, HRTIM_TIMERINDEX_TIMER_C, &pTimerCtl) != HAL_OK)
  {
    Error_Handler();
  }
  /* USER CODE BEGIN HRTIM1_Init 2 */
	HAL_HRTIM_WaveformCounterStart_IT(&hhrtim1, HRTIM_TIMERID_MASTER);
	HAL_HRTIM_WaveformCounterStart_IT(&hhrtim1, HRTIM_TIMERID_TIMER_A);
	HAL_HRTIM_WaveformCounterStart_IT(&hhrtim1, HRTIM_TIMERID_TIMER_B);
	HAL_HRTIM_WaveformCounterStart_IT(&hhrtim1, HRTIM_TIMERID_TIMER_C);
  /* USER CODE END HRTIM1_Init 2 */

}

static void MX_RTC_Init(void)
{

  RTC_TimeTypeDef sTime = {0};
  RTC_DateTypeDef sDate = {0};

  /** Initialize RTC Only
  */
  hrtc.Instance = RTC;
  hrtc.Init.HourFormat = RTC_HOURFORMAT_24;
  hrtc.Init.AsynchPrediv = 127;
  hrtc.Init.SynchPrediv = 255;
  hrtc.Init.OutPut = RTC_OUTPUT_DISABLE;
  hrtc.Init.OutPutRemap = RTC_OUTPUT_REMAP_NONE;
  hrtc.Init.OutPutPolarity = RTC_OUTPUT_POLARITY_HIGH;
  hrtc.Init.OutPutType = RTC_OUTPUT_TYPE_OPENDRAIN;
  hrtc.Init.OutPutPullUp = RTC_OUTPUT_PULLUP_NONE;
  if (HAL_RTC_Init(&hrtc) != HAL_OK)
  {
    Error_Handler();
  }

  /** Initialize RTC and set the Time and Date
  */
  sTime.Hours = 0x18;
  sTime.Minutes = 0x56;
  sTime.Seconds = 0x0;
  sTime.SubSeconds = 0x0;
  sTime.DayLightSaving = RTC_DAYLIGHTSAVING_NONE;
  sTime.StoreOperation = RTC_STOREOPERATION_RESET;
  if (HAL_RTC_SetTime(&hrtc, &sTime, RTC_FORMAT_BCD) != HAL_OK)
  {
    Error_Handler();
  }
  sDate.WeekDay = RTC_WEEKDAY_WEDNESDAY;
  sDate.Month = RTC_MONTH_FEBRUARY;
  sDate.Date = 0x26;
  sDate.Year = 0x25;

  if (HAL_RTC_SetDate(&hrtc, &sDate, RTC_FORMAT_BCD) != HAL_OK)
  {
    Error_Handler();
  }

}

static void MX_TIM1_Init(void)
{

  TIM_ClockConfigTypeDef sClockSourceConfig = {0};
  TIM_MasterConfigTypeDef sMasterConfig = {0};

  htim1.Instance = TIM1;
  htim1.Init.Prescaler = 0;
  htim1.Init.CounterMode = TIM_COUNTERMODE_UP;
  htim1.Init.Period = 0;
  htim1.Init.ClockDivision = TIM_CLOCKDIVISION_DIV1;
  htim1.Init.RepetitionCounter = 0;
  htim1.Init.AutoReloadPreload = TIM_AUTORELOAD_PRELOAD_DISABLE;
  if (HAL_TIM_Base_Init(&htim1) != HAL_OK)
  {
    Error_Handler();
  }
  sClockSourceConfig.ClockSource = TIM_CLOCKSOURCE_INTERNAL;
  if (HAL_TIM_ConfigClockSource(&htim1, &sClockSourceConfig) != HAL_OK)
  {
    Error_Handler();
  }
  sMasterConfig.MasterOutputTrigger = TIM_TRGO_RESET;
  sMasterConfig.MasterOutputTrigger2 = TIM_TRGO2_RESET;
  sMasterConfig.MasterSlaveMode = TIM_MASTERSLAVEMODE_DISABLE;
  if (HAL_TIMEx_MasterConfigSynchronization(&htim1, &sMasterConfig) != HAL_OK)
  {
    Error_Handler();
  }

}

static void MX_USART1_UART_Init(void)
{

  huart1.Instance = USART1;
  huart1.Init.BaudRate = 115200;
  huart1.Init.WordLength = UART_WORDLENGTH_8B;
  huart1.Init.StopBits = UART_STOPBITS_1;
  huart1.Init.Parity = UART_PARITY_NONE;
  huart1.Init.Mode = UART_MODE_TX_RX;
  huart1.Init.HwFlowCtl = UART_HWCONTROL_RTS_CTS;
  huart1.Init.OverSampling = UART_OVERSAMPLING_16;
  huart1.Init.OneBitSampling = UART_ONE_BIT_SAMPLE_DISABLE;
  huart1.Init.ClockPrescaler = UART_PRESCALER_DIV1;
  huart1.AdvancedInit.AdvFeatureInit = UART_ADVFEATURE_NO_INIT;
  if (HAL_UART_Init(&huart1) != HAL_OK)
  {
    Error_Handler();
  }
  if (HAL_UARTEx_SetTxFifoThreshold(&huart1, UART_TXFIFO_THRESHOLD_1_8) != HAL_OK)
  {
    Error_Handler();
  }
  if (HAL_UARTEx_SetRxFifoThreshold(&huart1, UART_RXFIFO_THRESHOLD_1_8) != HAL_OK)
  {
    Error_Handler();
  }
  if (HAL_UARTEx_DisableFifoMode(&huart1) != HAL_OK)
  {
    Error_Handler();
  }

}

static void MX_DMA_Init(void)
{

  /* DMA controller clock enable */
  __HAL_RCC_DMAMUX1_CLK_ENABLE();
  __HAL_RCC_DMA1_CLK_ENABLE();

  /* DMA interrupt init */
  /* DMA1_Channel1_IRQn interrupt configuration */
  HAL_NVIC_SetPriority(DMA1_Channel1_IRQn, 0, 0);
  HAL_NVIC_EnableIRQ(DMA1_Channel1_IRQn);
  /* DMA1_Channel2_IRQn interrupt configuration */
  HAL_NVIC_SetPriority(DMA1_Channel2_IRQn, 0, 0);
  HAL_NVIC_EnableIRQ(DMA1_Channel2_IRQn);
  /* DMA1_Channel3_IRQn interrupt configuration */
  HAL_NVIC_SetPriority(DMA1_Channel3_IRQn, 0, 0);
  HAL_NVIC_EnableIRQ(DMA1_Channel3_IRQn);
  /* DMA1_Channel4_IRQn interrupt configuration */
  HAL_NVIC_SetPriority(DMA1_Channel4_IRQn, 0, 0);
  HAL_NVIC_EnableIRQ(DMA1_Channel4_IRQn);
  /* DMA1_Channel5_IRQn interrupt configuration */
  HAL_NVIC_SetPriority(DMA1_Channel5_IRQn, 0, 0);
  HAL_NVIC_EnableIRQ(DMA1_Channel5_IRQn);
  /* DMA1_Channel6_IRQn interrupt configuration */
  HAL_NVIC_SetPriority(DMA1_Channel6_IRQn, 0, 0);
  HAL_NVIC_EnableIRQ(DMA1_Channel6_IRQn);

}

static void MX_GPIO_Init(void)
{
  GPIO_InitTypeDef GPIO_InitStruct = {0};

  /* GPIO Ports Clock Enable */
  __HAL_RCC_GPIOC_CLK_ENABLE();
  __HAL_RCC_GPIOF_CLK_ENABLE();
  __HAL_RCC_GPIOA_CLK_ENABLE();
  __HAL_RCC_GPIOB_CLK_ENABLE();
  __HAL_RCC_GPIOD_CLK_ENABLE();

  /*Configure GPIO pin Output Level */
  HAL_GPIO_WritePin(GPIOC, SEL_0_96_111_Pin|SEL_2_0_15_Pin|SEL_3_0_15_Pin|SEL_0_0_15_Pin
                          |SEL_1_0_15_Pin|SEL_2_48_63_Pin|SEL_3_48_63_Pin|SEL_1_64_79_Pin
                          |SEL_0_64_79_Pin|SEL_2_112_127_Pin|SEL_3_112_127_Pin|SEL_1_112_127_Pin
                          |SEL_3_80_95_Pin|SEL_2_80_95_Pin, GPIO_PIN_RESET);

  /*Configure GPIO pin Output Level */
  HAL_GPIO_WritePin(GPIOA, SEL_3_16_31_Pin|SEL_2_16_31_Pin|SEL_1_16_31_Pin|SEL_0_16_31_Pin
                          |SEL_0_112_127_Pin, GPIO_PIN_RESET);

  /*Configure GPIO pin Output Level */
  HAL_GPIO_WritePin(GPIOB, SEL_0_48_63_Pin|SEL_1_48_63_Pin|SEL_1_96_111_Pin|SEL_2_96_111_Pin
                          |SEL_3_64_79_Pin|SEL_2_64_79_Pin|SEL_1_80_95_Pin|SEL_2_32_47_Pin
                          |SEL_3_32_47_Pin|SEL_0_32_47_Pin|SEL_1_32_47_Pin|SEL_3_96_111_Pin, GPIO_PIN_RESET);

  /*Configure GPIO pin Output Level */
  HAL_GPIO_WritePin(SEL_0_80_95_GPIO_Port, SEL_0_80_95_Pin, GPIO_PIN_RESET);

  /*Configure GPIO pin : SEL_0_96_111_Pin */
  GPIO_InitStruct.Pin = SEL_0_96_111_Pin;
  GPIO_InitStruct.Mode = GPIO_MODE_OUTPUT_PP;
  GPIO_InitStruct.Pull = GPIO_NOPULL;
  GPIO_InitStruct.Speed = GPIO_SPEED_FREQ_LOW;
  HAL_GPIO_Init(SEL_0_96_111_GPIO_Port, &GPIO_InitStruct);

  /*Configure GPIO pins : SEL_2_0_15_Pin SEL_3_0_15_Pin SEL_0_0_15_Pin SEL_1_0_15_Pin
                           SEL_2_48_63_Pin SEL_3_48_63_Pin SEL_1_64_79_Pin SEL_0_64_79_Pin
                           SEL_2_112_127_Pin SEL_3_112_127_Pin SEL_1_112_127_Pin SEL_3_80_95_Pin
                           SEL_2_80_95_Pin */
  GPIO_InitStruct.Pin = SEL_2_0_15_Pin|SEL_3_0_15_Pin|SEL_0_0_15_Pin|SEL_1_0_15_Pin
                          |SEL_2_48_63_Pin|SEL_3_48_63_Pin|SEL_1_64_79_Pin|SEL_0_64_79_Pin
                          |SEL_2_112_127_Pin|SEL_3_112_127_Pin|SEL_1_112_127_Pin|SEL_3_80_95_Pin
                          |SEL_2_80_95_Pin;
  GPIO_InitStruct.Mode = GPIO_MODE_OUTPUT_PP;
  GPIO_InitStruct.Pull = GPIO_NOPULL;
  GPIO_InitStruct.Speed = GPIO_SPEED_FREQ_VERY_HIGH;
  HAL_GPIO_Init(GPIOC, &GPIO_InitStruct);

  /*Configure GPIO pins : SEL_3_16_31_Pin SEL_2_16_31_Pin SEL_1_16_31_Pin SEL_0_16_31_Pin
                           SEL_0_112_127_Pin */
  GPIO_InitStruct.Pin = SEL_3_16_31_Pin|SEL_2_16_31_Pin|SEL_1_16_31_Pin|SEL_0_16_31_Pin
                          |SEL_0_112_127_Pin;
  GPIO_InitStruct.Mode = GPIO_MODE_OUTPUT_PP;
  GPIO_InitStruct.Pull = GPIO_NOPULL;
  GPIO_InitStruct.Speed = GPIO_SPEED_FREQ_VERY_HIGH;
  HAL_GPIO_Init(GPIOA, &GPIO_InitStruct);

  /*Configure GPIO pins : SEL_0_48_63_Pin SEL_1_48_63_Pin SEL_1_96_111_Pin SEL_2_96_111_Pin
                           SEL_3_64_79_Pin SEL_2_64_79_Pin SEL_1_80_95_Pin SEL_2_32_47_Pin
                           SEL_3_32_47_Pin SEL_0_32_47_Pin SEL_1_32_47_Pin SEL_3_96_111_Pin */
  GPIO_InitStruct.Pin = SEL_0_48_63_Pin|SEL_1_48_63_Pin|SEL_1_96_111_Pin|SEL_2_96_111_Pin
                          |SEL_3_64_79_Pin|SEL_2_64_79_Pin|SEL_1_80_95_Pin|SEL_2_32_47_Pin
                          |SEL_3_32_47_Pin|SEL_0_32_47_Pin|SEL_1_32_47_Pin|SEL_3_96_111_Pin;
  GPIO_InitStruct.Mode = GPIO_MODE_OUTPUT_PP;
  GPIO_InitStruct.Pull = GPIO_NOPULL;
  GPIO_InitStruct.Speed = GPIO_SPEED_FREQ_VERY_HIGH;
  HAL_GPIO_Init(GPIOB, &GPIO_InitStruct);

  /*Configure GPIO pin : SEL_0_80_95_Pin */
  GPIO_InitStruct.Pin = SEL_0_80_95_Pin;
  GPIO_InitStruct.Mode = GPIO_MODE_OUTPUT_PP;
  GPIO_InitStruct.Pull = GPIO_NOPULL;
  GPIO_InitStruct.Speed = GPIO_SPEED_FREQ_VERY_HIGH;
  HAL_GPIO_Init(SEL_0_80_95_GPIO_Port, &GPIO_InitStruct);

  /**/
  __HAL_SYSCFG_FASTMODEPLUS_ENABLE(SYSCFG_FASTMODEPLUS_PB6);

  /**/
  __HAL_SYSCFG_FASTMODEPLUS_ENABLE(SYSCFG_FASTMODEPLUS_PB7);

  /**/
  __HAL_SYSCFG_FASTMODEPLUS_ENABLE(SYSCFG_FASTMODEPLUS_PB9);

/* USER CODE BEGIN MX_GPIO_Init_2 */
GPIOA->OSPEEDR = 0xFFFFFFFF;
GPIOB->OSPEEDR = 0xFFFFFFFF;
GPIOC->OSPEEDR = 0xFFFFFFFF;
GPIOD->OSPEEDR = 0xFFFFFFFF;
/* USER CODE END MX_GPIO_Init_2 */
}

void Error_Handler(void)
{
  __disable_irq();
  while (1)
  {
  }
}
